AUTOSAR XML (schema 4-0-3)
package /ComponentTypes
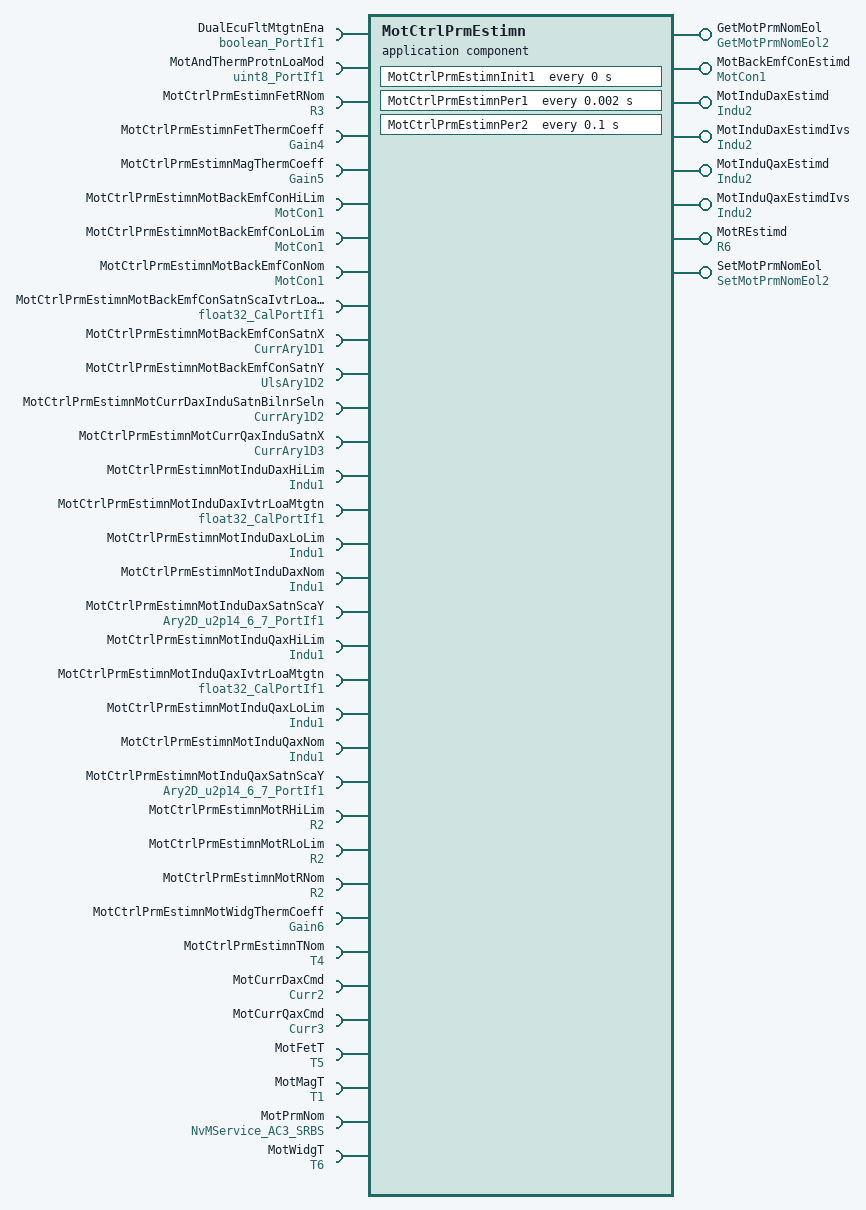
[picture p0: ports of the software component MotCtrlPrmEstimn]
  application sw component type MotCtrlPrmEstimn
    8 x provide port:
      GetMotPrmNomEol: server-com-spec{operation=Oper, queue-length=1}, provided-interface=GetMotPrmNomEol2
      MotBackEmfConEstimd: nonqueued-sender-com-spec{data-element=Val, init-value=0.025}, provided-interface=MotCon1
      MotInduDaxEstimd: nonqueued-sender-com-spec{data-element=Val, init-value=0.00011889}, provided-interface=Indu2
      MotInduDaxEstimdIvs: nonqueued-sender-com-spec{data-element=Val, init-value=8412}, provided-interface=Indu2
      MotInduQaxEstimd: nonqueued-sender-com-spec{data-element=Val, init-value=0.00011889}, provided-interface=Indu2
      MotInduQaxEstimdIvs: nonqueued-sender-com-spec{data-element=Val, init-value=8412}, provided-interface=Indu2
      MotREstimd: nonqueued-sender-com-spec{data-element=Val, init-value=0.005}, provided-interface=R6
      SetMotPrmNomEol: server-com-spec{operation=Oper, queue-length=1}, provided-interface=SetMotPrmNomEol2
    34 x require port:
      DualEcuFltMtgtnEna: nonqueued-receiver-com-spec{data-element=Logl, filter=data-filter-type=ALWAYS, init-value=0}, required-interface=boolean_PortIf1
      MotAndThermProtnLoaMod: nonqueued-receiver-com-spec{data-element=Val, filter=data-filter-type=ALWAYS, init-value=0}, required-interface=uint8_PortIf1
      MotCtrlPrmEstimnFetRNom: parameter-require-com-spec{init-value=0.0052, parameter=Val}, required-interface=R3
      MotCtrlPrmEstimnFetThermCoeff: parameter-require-com-spec{init-value=0.005, parameter=Val}, required-interface=Gain4
      MotCtrlPrmEstimnMagThermCoeff: parameter-require-com-spec{init-value=-0.001, parameter=Val}, required-interface=Gain5
      MotCtrlPrmEstimnMotBackEmfConHiLim: parameter-require-com-spec{init-value=0.045, parameter=Val}, required-interface=MotCon1
      MotCtrlPrmEstimnMotBackEmfConLoLim: parameter-require-com-spec{init-value=0.031, parameter=Val}, required-interface=MotCon1
      MotCtrlPrmEstimnMotBackEmfConNom: parameter-require-com-spec{init-value=0.04, parameter=Val}, required-interface=MotCon1
      MotCtrlPrmEstimnMotBackEmfConSatnScaIvtrLoaMtgtn: parameter-require-com-spec{init-value=1.0, parameter=Val}, required-interface=float32_CalPortIf1
      MotCtrlPrmEstimnMotBackEmfConSatnX: parameter-require-com-spec{init-value=[0, 10, 20, 30, 40, 50, 60, 70, 80, 90, 100, 110, 120, 130, 150, 170], parameter=Ary1D}, required-interface=CurrAry1D1
      MotCtrlPrmEstimnMotBackEmfConSatnY: parameter-require-com-spec{init-value=[1, 1, 1, 1, 1, 1, 1, 1, 1, 1, 1, 0.999145, 0.99707, 0.993408, 0.98236, 0.968566], parameter=Ary1D}, required-interface=UlsAry1D2
      MotCtrlPrmEstimnMotCurrDaxInduSatnBilnrSeln: parameter-require-com-spec{init-value=[0, 25, 50, 75, 100, 125], parameter=Ary1D}, required-interface=CurrAry1D2
      MotCtrlPrmEstimnMotCurrQaxInduSatnX: parameter-require-com-spec{init-value=[0, 25, 50, 75, 100, 125, 150], parameter=Ary1D}, required-interface=CurrAry1D3
      MotCtrlPrmEstimnMotInduDaxHiLim: parameter-require-com-spec{init-value=0.00013, parameter=Val}, required-interface=Indu1
      MotCtrlPrmEstimnMotInduDaxIvtrLoaMtgtn: parameter-require-com-spec{init-value=0.00013, parameter=Val}, required-interface=float32_CalPortIf1
      MotCtrlPrmEstimnMotInduDaxLoLim: parameter-require-com-spec{init-value=0.0001, parameter=Val}, required-interface=Indu1
      MotCtrlPrmEstimnMotInduDaxNom: parameter-require-com-spec{init-value=0.00011889, parameter=Val}, required-interface=Indu1
      MotCtrlPrmEstimnMotInduDaxSatnScaY: parameter-require-com-spec{init-value=6 x [16384, 16384, 16384, 16384, 16384, 16305, 16096], parameter=Ary2D}, required-interface=Ary2D_u2p14_6_7_PortIf1
      MotCtrlPrmEstimnMotInduQaxHiLim: parameter-require-com-spec{init-value=0.00013, parameter=Val}, required-interface=Indu1
      MotCtrlPrmEstimnMotInduQaxIvtrLoaMtgtn: parameter-require-com-spec{init-value=0.00013, parameter=Val}, required-interface=float32_CalPortIf1
      MotCtrlPrmEstimnMotInduQaxLoLim: parameter-require-com-spec{init-value=0.0001, parameter=Val}, required-interface=Indu1
      MotCtrlPrmEstimnMotInduQaxNom: parameter-require-com-spec{init-value=0.00011889, parameter=Val}, required-interface=Indu1
      MotCtrlPrmEstimnMotInduQaxSatnScaY: parameter-require-com-spec{init-value=6 x [16384, 16384, 16384, 16384, 16384, 16305, 16096], parameter=Ary2D}, required-interface=Ary2D_u2p14_6_7_PortIf1
      MotCtrlPrmEstimnMotRHiLim: parameter-require-com-spec{init-value=0.032, parameter=Val}, required-interface=R2
      MotCtrlPrmEstimnMotRLoLim: parameter-require-com-spec{init-value=0.01246, parameter=Val}, required-interface=R2
      MotCtrlPrmEstimnMotRNom: parameter-require-com-spec{init-value=0.0139, parameter=Val}, required-interface=R2
      MotCtrlPrmEstimnMotWidgThermCoeff: parameter-require-com-spec{init-value=0.0039, parameter=Val}, required-interface=Gain6
      MotCtrlPrmEstimnTNom: parameter-require-com-spec{init-value=25, parameter=Val}, required-interface=T4
      MotCurrDaxCmd: nonqueued-receiver-com-spec{data-element=Val, filter=data-filter-type=ALWAYS, init-value=0}, required-interface=Curr2
      MotCurrQaxCmd: nonqueued-receiver-com-spec{data-element=Val, filter=data-filter-type=ALWAYS, init-value=0}, required-interface=Curr3
      MotFetT: nonqueued-receiver-com-spec{data-element=Val, filter=data-filter-type=ALWAYS, init-value=0}, required-interface=T5
      MotMagT: nonqueued-receiver-com-spec{data-element=Val, filter=data-filter-type=ALWAYS, init-value=0}, required-interface=T1
      MotPrmNom: required-com-specs=[EraseBlock, GetErrorStatus, InvalidateNvBlock, ReadBlock, SetRamBlockStatus, WriteBlock], required-interface=NvMService_AC3_SRBS
      MotWidgT: nonqueued-receiver-com-spec{data-element=Val, filter=data-filter-type=ALWAYS, init-value=0}, required-interface=T6
    behavior MotCtrlPrmEstimn_InternalBehavior: data-type-mapping=Nexteer
      ar-typed-per-instance-memorys:
        10 x data, all with sw-calibration-access=READ-ONLY:
          dMotCtrlPrmEstimnCtrlrREstimdPreLim: type=R6
          dMotCtrlPrmEstimnFetRFfEstimd: type=R8
          dMotCtrlPrmEstimnMotBackEmfConEstimdPreLim: type=MotCon1
          dMotCtrlPrmEstimnMotBackEmfConEstimdSatnSca: type=Uls2
          dMotCtrlPrmEstimnMotInduEstimdPreLimDax: type=Indu1
          dMotCtrlPrmEstimnMotInduEstimdPreLimQax: type=Indu1
          dMotCtrlPrmEstimnMotInduEstimdSatnScaDax: type=Uls2
          dMotCtrlPrmEstimnMotInduEstimdSatnScaQax: type=Uls2
          dMotCtrlPrmEstimnMotRFfEstimd: type=R6
          MotPrmNom: type=MotPrmNomEolRecAppl3
      operation invoked event OIT_GetMotPrmNomEol_Oper_GetMotPrmNomEol_Oper: start-on-event=GetMotPrmNomEol_Oper, operation=GetMotPrmNomEol.Oper
      timing event MotCtrlPrmEstimn_InitEvent: start-on-event=MotCtrlPrmEstimnInit1, period=0
      timing event TMT_MotCtrlPrmEstimnPer1: start-on-event=MotCtrlPrmEstimnPer1, period=0.002
      timing event TMT_MotCtrlPrmEstimnPer2: start-on-event=MotCtrlPrmEstimnPer2, period=0.1
      operation invoked event OIT_SetMotPrmNomEol_Oper_SetMotPrmNomEol_Oper: start-on-event=SetMotPrmNomEol_Oper, operation=SetMotPrmNomEol.Oper
      explicit-inter-runnable-variables:
        data MotBackEmfConFf: type=MotCon1, init-value=0.03993
      5 x runnable:
        GetMotPrmNomEol_Oper
        MotCtrlPrmEstimnInit1
          data-send-points:
            4 x access:
              SEND_MotBackEmfConEstimd_Val: accessed-variable=MotBackEmfConEstimd.Val
              SEND_MotInduDaxEstimd_Val: accessed-variable=MotInduDaxEstimd.Val
              SEND_MotInduQaxEstimd_Val: accessed-variable=MotInduQaxEstimd.Val
              SEND_MotREstimd_Val: accessed-variable=MotREstimd.Val
          sync call SC_MotPrmNom_GetErrorStatus: operation=MotPrmNom.GetErrorStatus, timeout=0
          sync call SC_MotPrmNom_SetRamBlockStatus: operation=MotPrmNom.SetRamBlockStatus, timeout=0
        MotCtrlPrmEstimnPer1
          data-receive-point-by-arguments:
            4 x access:
              REC_DualEcuFltMtgtnEna_Logl: accessed-variable=DualEcuFltMtgtnEna.Logl
              REC_MotAndThermProtnLoaMod_Val: accessed-variable=MotAndThermProtnLoaMod.Val
              REC_MotCurrDaxCmd_Val: accessed-variable=MotCurrDaxCmd.Val
              REC_MotCurrQaxCmd_Val: accessed-variable=MotCurrQaxCmd.Val
          data-send-points:
            5 x access:
              SEND_MotBackEmfConEstimd_Val: accessed-variable=MotBackEmfConEstimd.Val
              SEND_MotCtrlMotInduDaxEstimdIvs_Val: accessed-variable=MotInduDaxEstimdIvs.Val
              SEND_MotCtrlMotInduQaxEstimdIvs_Val: accessed-variable=MotInduQaxEstimdIvs.Val
              SEND_MotInduDaxEstimd_Val: accessed-variable=MotInduDaxEstimd.Val
              SEND_MotInduQaxEstimd_Val: accessed-variable=MotInduQaxEstimd.Val
          read-local-variables:
            access READ_MotBackEmfConFf: accessed-variable=MotBackEmfConFf
        MotCtrlPrmEstimnPer2
          data-receive-point-by-arguments:
            access REC_MotFetT_Val: accessed-variable=MotFetT.Val
            access REC_MotMagT_Val: accessed-variable=MotMagT.Val
            access REC_MotWidgT_Val: accessed-variable=MotWidgT.Val
          data-send-points:
            access SEND_MotREstimd_Val: accessed-variable=MotREstimd.Val
          written-local-variables:
            access WRITE_MotBackEmfConFf: accessed-variable=MotBackEmfConFf
        SetMotPrmNomEol_Oper
          sync call SC_MotPrmNom_SetRamBlockStatus: operation=MotPrmNom.SetRamBlockStatus, timeout=0
  swc implementation MotCtrlPrmEstimn_Implementation: behavior=MotCtrlPrmEstimn_InternalBehavior
    code-descriptors:
      code Default: artifact-descriptors=autosar-engineering-object={short-label=Default, category=SWSRC}
